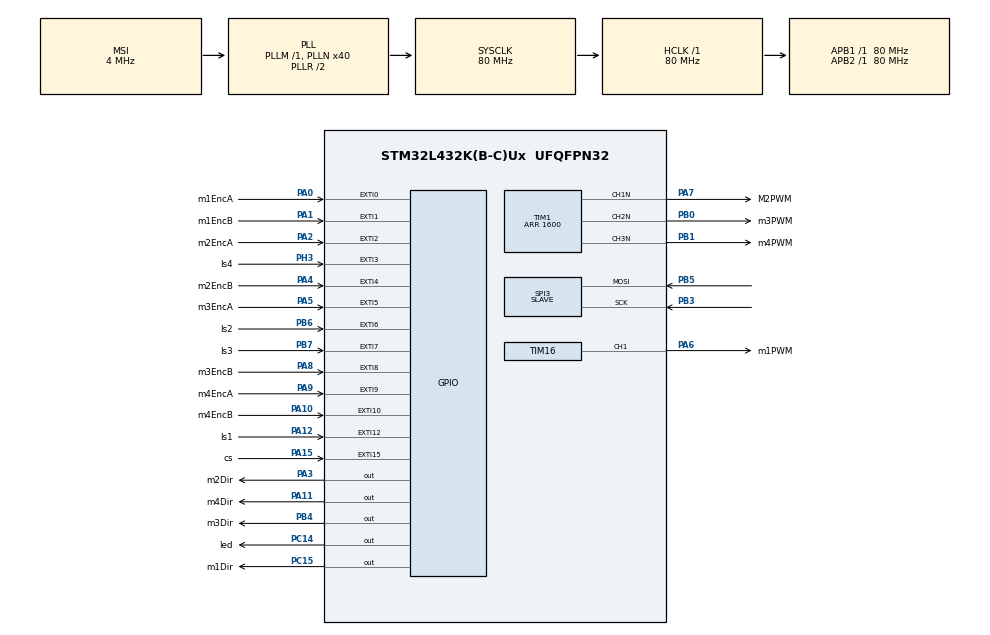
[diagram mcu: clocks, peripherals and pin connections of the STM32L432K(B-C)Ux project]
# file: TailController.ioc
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Dma.Request0=SPI3_RX
Dma.SPI3_RX.0.Direction=DMA_PERIPH_TO_MEMORY
Dma.SPI3_RX.0.Instance=DMA2_Channel1
Dma.SPI3_RX.0.MemDataAlignment=DMA_MDATAALIGN_HALFWORD
Dma.SPI3_RX.0.MemInc=DMA_MINC_ENABLE
Dma.SPI3_RX.0.Mode=DMA_NORMAL
Dma.SPI3_RX.0.PeriphDataAlignment=DMA_PDATAALIGN_HALFWORD
Dma.SPI3_RX.0.PeriphInc=DMA_PINC_DISABLE
Dma.SPI3_RX.0.Priority=DMA_PRIORITY_HIGH
Mcu.Family=STM32L4
Mcu.Name=STM32L432K(B-C)Ux
Mcu.Package=UFQFPN32
NVIC.DMA2_Channel1_IRQn=true\:0\:0\:false\:false\:true\:false\:true
NVIC.EXTI0_IRQn=true\:0\:0\:false\:false\:true\:true\:true
NVIC.EXTI15_10_IRQn=true\:0\:0\:false\:false\:true\:true\:true
NVIC.EXTI1_IRQn=true\:0\:0\:false\:false\:true\:true\:true
NVIC.EXTI2_IRQn=true\:0\:0\:false\:false\:true\:true\:true
NVIC.EXTI3_IRQn=true\:0\:0\:false\:false\:true\:true\:true
NVIC.EXTI4_IRQn=true\:0\:0\:false\:false\:true\:true\:true
NVIC.EXTI9_5_IRQn=true\:0\:0\:false\:false\:true\:true\:true
NVIC.PriorityGroup=NVIC_PRIORITYGROUP_4
NVIC.TIM7_IRQn=true\:0\:0\:false\:false\:true\:true\:true
PA0.GPIO_Label=m1EncA
PA0.Signal=SharedStack_PA0
PA0.Stacked=true
PA1.GPIO_Label=m1EncB
PA1.Signal=SharedStack_PA1
PA1.Stacked=true
PA10.GPIO_Label=m4EncB
PA10.Signal=SharedStack_PA10
PA10.Stacked=true
PA11.GPIO_Label=m4Dir
PA11.GPIO_ModeDefaultOutputPP=GPIO_MODE_OUTPUT_PP
PA11.GPIO_PuPd=GPIO_PULLDOWN
PA11.GPIO_Speed=GPIO_SPEED_FREQ_LOW
PA11.PinState=GPIO_PIN_RESET
PA11.Signal=GPIO_Output
PA12.GPIO_Label=ls1
PA12.Signal=GPXTI12
PA13\ (JTMS-SWDIO).Mode=Serial_Wire
PA13\ (JTMS-SWDIO).Signal=SYS_JTMS-SWDIO
PA14\ (JTCK-SWCLK).Mode=Serial_Wire
PA14\ (JTCK-SWCLK).Signal=SYS_JTCK-SWCLK
PA15\ (JTDI).GPIO_Label=cs
PA15\ (JTDI).Signal=GPXTI15
PA2.GPIO_Label=m2EncA
PA2.Signal=SharedStack_PA2
PA2.Stacked=true
PA3.GPIO_Label=m2Dir
PA3.GPIO_ModeDefaultOutputPP=GPIO_MODE_OUTPUT_PP
PA3.GPIO_PuPd=GPIO_PULLDOWN
PA3.GPIO_Speed=GPIO_SPEED_FREQ_LOW
PA3.PinState=GPIO_PIN_RESET
PA3.Signal=GPIO_Output
PA4.GPIO_Label=m2EncB
PA4.Signal=SharedStack_PA4
PA4.Stacked=true
PA5.GPIO_Label=m3EncA
PA5.Signal=SharedStack_PA5
PA5.Stacked=true
PA6.GPIO_Label=m1PWM
PA6.Signal=S_TIM16_CH1
PA7.GPIO_Label=M2PWM
PA7.GPIO_Speed=GPIO_SPEED_FREQ_VERY_HIGH
PA7.Mode=PWM Generation1 CH1N
PA7.Signal=TIM1_CH1N
PA8.GPIO_Label=m3EncB
PA8.Signal=SharedStack_PA8
PA8.Stacked=true
PA9.GPIO_Label=m4EncA
PA9.Signal=SharedStack_PA9
PA9.Stacked=true
PB0.GPIO_Label=m3PWM
PB0.GPIO_Speed=GPIO_SPEED_FREQ_VERY_HIGH
PB0.Mode=PWM Generation2 CH2N
PB0.Signal=TIM1_CH2N
PB1.GPIO_Label=m4PWM
PB1.GPIO_Speed=GPIO_SPEED_FREQ_VERY_HIGH
PB1.Mode=PWM Generation3 CH3N
PB1.Signal=TIM1_CH3N
PB3\ (JTDO-TRACESWO).Mode=RX_Only_Simplex_Unidirect_Slave
PB3\ (JTDO-TRACESWO).Signal=SPI3_SCK
PB4\ (NJTRST).GPIO_Label=m3Dir
PB4\ (NJTRST).GPIO_ModeDefaultOutputPP=GPIO_MODE_OUTPUT_PP
PB4\ (NJTRST).GPIO_PuPd=GPIO_PULLDOWN
PB4\ (NJTRST).GPIO_Speed=GPIO_SPEED_FREQ_LOW
PB4\ (NJTRST).PinState=GPIO_PIN_RESET
PB4\ (NJTRST).Signal=GPIO_Output
PB5.Mode=RX_Only_Simplex_Unidirect_Slave
PB5.Signal=SPI3_MOSI
PB6.GPIO_Label=ls2
PB6.Signal=GPXTI6
PB7.GPIO_Label=ls3
PB7.Signal=GPXTI7
PC14-OSC32_IN\ (PC14).GPIO_Label=led
PC14-OSC32_IN\ (PC14).GPIO_ModeDefaultOutputPP=GPIO_MODE_OUTPUT_PP
PC14-OSC32_IN\ (PC14).GPIO_PuPd=GPIO_PULLDOWN
PC14-OSC32_IN\ (PC14).GPIO_Speed=GPIO_SPEED_FREQ_LOW
PC14-OSC32_IN\ (PC14).PinState=GPIO_PIN_RESET
PC14-OSC32_IN\ (PC14).Signal=GPIO_Output
PC15-OSC32_OUT\ (PC15).GPIO_Label=m1Dir
PC15-OSC32_OUT\ (PC15).GPIO_ModeDefaultOutputPP=GPIO_MODE_OUTPUT_PP
PC15-OSC32_OUT\ (PC15).GPIO_PuPd=GPIO_PULLDOWN
PC15-OSC32_OUT\ (PC15).GPIO_Speed=GPIO_SPEED_FREQ_LOW
PC15-OSC32_OUT\ (PC15).PinState=GPIO_PIN_RESET
PC15-OSC32_OUT\ (PC15).Signal=GPIO_Output
PH3-BOOT0.GPIO_Label=ls4
PH3-BOOT0.Signal=GPXTI3
ProjectManager.HeapSize=0x200
ProjectManager.StackSize=0x400
ProjectManager.TargetToolchain=SW4STM32
RCC.AHBFreq_Value=80000000
RCC.APB1Freq_Value=80000000
RCC.APB1TimFreq_Value=80000000
RCC.APB2Freq_Value=80000000
RCC.APB2TimFreq_Value=80000000
RCC.CortexFreq_Value=80000000
RCC.HCLKFreq_Value=80000000
RCC.HSE_VALUE=8000000
RCC.HSI48_VALUE=48000000
RCC.HSI_VALUE=16000000
RCC.LSE_VALUE=32768
RCC.MSI_VALUE=4000000
RCC.PLLN=40
RCC.SYSCLKFreq_VALUE=80000000
RCC.SYSCLKSource=RCC_SYSCLKSOURCE_PLLCLK
RCC.VCOOutputFreq_Value=160000000
SH.S_TIM16_CH1.0=TIM16_CH1,PWM Generation1 CH1
SH.SharedStack_PA0.0=GPIO_EXTI0
SH.SharedStack_PA0.1=GPIO_Input+0
SH.SharedStack_PA1.0=GPIO_EXTI1
SH.SharedStack_PA1.1=GPIO_Input+0
SH.SharedStack_PA10.0=GPIO_EXTI10
SH.SharedStack_PA10.1=GPIO_Input+0
SH.SharedStack_PA2.0=GPIO_EXTI2
SH.SharedStack_PA2.1=GPIO_Input+0
SH.SharedStack_PA4.0=GPIO_EXTI4
SH.SharedStack_PA4.1=GPIO_Input+0
SH.SharedStack_PA5.0=GPIO_EXTI5
SH.SharedStack_PA5.1=GPIO_Input+0
SH.SharedStack_PA8.0=GPIO_EXTI8
SH.SharedStack_PA8.1=GPIO_Input+0
SH.SharedStack_PA9.0=GPIO_EXTI9
SH.SharedStack_PA9.1=GPIO_Input+0
SPI3.DataSize=SPI_DATASIZE_16BIT
SPI3.Direction=SPI_DIRECTION_2LINES_RXONLY
SPI3.Mode=SPI_MODE_SLAVE
SPI3.VirtualType=VM_SLAVE
TIM1.Channel-PWM\ Generation1\ CH1N=TIM_CHANNEL_1
TIM1.Channel-PWM\ Generation2\ CH2N=TIM_CHANNEL_2
TIM1.Channel-PWM\ Generation3\ CH3N=TIM_CHANNEL_3
TIM1.OCFastMode_PWM-PWM\ Generation1\ CH1N=TIM_OCFAST_ENABLE
TIM1.OCFastMode_PWM-PWM\ Generation2\ CH2N=TIM_OCFAST_ENABLE
TIM1.OCFastMode_PWM-PWM\ Generation3\ CH3N=TIM_OCFAST_ENABLE
TIM1.Period=1600
TIM1.Pulse-PWM\ Generation1\ CH1N=800
TIM1.Pulse-PWM\ Generation2\ CH2N=800
TIM1.Pulse-PWM\ Generation3\ CH3N=800
TIM1.RepetitionCounter=0
TIM16.Channel=TIM_CHANNEL_1
TIM16.Prescaler=1600
TIM16.Pulse=800
TIM7.Period=1000
VP_TIM16_VS_ClockSourceINT.Mode=Enable_Timer
VP_TIM7_VS_ClockSourceINT.Mode=Enable_Timer
board=custom

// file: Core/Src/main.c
/* USER CODE BEGIN Header */
/**
 ******************************************************************************
 * @file           : main.c
 * @brief          : Main program body
 ******************************************************************************
 * @attention
 *
 * <h2><center>&copy; Copyright (c) 2019 STMicroelectronics.
 * All rights reserved.</center></h2>
 *
 * This software component is licensed by ST under BSD 3-Clause license,
 * the "License"; You may not use this file except in compliance with the
 * License. You may obtain a copy of the License at:
 *                        opensource.org/licenses/BSD-3-Clause
 *
 ******************************************************************************
 */
/* USER CODE END Header */

#include "main.h"
#include <stdbool.h>
#include "PID.h"

/* USER CODE BEGIN PM */
#define PWM_Period 18000

/* USER CODE END PM */

SPI_HandleTypeDef hspi3;
DMA_HandleTypeDef hdma_spi3_rx;

TIM_HandleTypeDef htim1;
TIM_HandleTypeDef htim7;
TIM_HandleTypeDef htim16;

extern int64_t m1Enc ,m2Enc, m3Enc, m4Enc;
int m1A, m1B, m2A, m2B, m3A, m3B, m4A, m4B;
float M1Out, M2Out, M3Out, M4Out;

extern bool m1Homed, m2Homed , m3Homed , m4Homed ;

PidType M1 ;
PidType M2 ;
PidType M3 ;
PidType M4 ;

int64_t M1SetPoint, M2SetPoint, M3SetPoint, M4SetPoint;
int16_t _TXData[6];

void SystemClock_Config(void);
static void MX_GPIO_Init(void);
static void MX_DMA_Init(void);
static void MX_TIM1_Init(void);
static void MX_TIM16_Init(void);
static void MX_SPI3_Init(void);
static void MX_TIM7_Init(void);
void runControllers(void);
void HomeMotors(int motor);
void ConfigCOntrollers();
int PCLK1_Freq;

int main(void)
{

	/* MCU Configuration--------------------------------------------------------*/

	/* Reset of all peripherals, Initializes the Flash interface and the Systick. */
	HAL_Init();

	/* Configure the system clock */
	SystemClock_Config();

	/* Initialize all configured peripherals */
	MX_GPIO_Init();
	MX_DMA_Init();
	MX_TIM1_Init();
	MX_TIM16_Init();
	MX_SPI3_Init();
	MX_TIM7_Init();
	ConfigControllers();

	M1SetPoint = 342000;
	M2SetPoint = 342000;
	M3SetPoint = 342000;
	M4SetPoint = 300;

	PCLK1_Freq = HAL_RCC_GetPCLK2Freq();
	if (HAL_TIM_PWM_Start(&htim16, TIM_CHANNEL_1) != HAL_OK)
	{
		Error_Handler();
	}
	if (HAL_TIMEx_PWMN_Start(&htim1, TIM_CHANNEL_1) != HAL_OK)
	{
		Error_Handler();
	}
	if (HAL_TIMEx_PWMN_Start(&htim1, TIM_CHANNEL_2) != HAL_OK)
	{
		Error_Handler();
	}
	if (HAL_TIMEx_PWMN_Start(&htim1, TIM_CHANNEL_3) != HAL_OK)
	{
		Error_Handler();
	}
	__HAL_TIM_SET_AUTORELOAD(&htim16, PCLK1_Freq / PWM_Period);

	__HAL_TIM_SET_AUTORELOAD(&htim1, PCLK1_Freq / PWM_Period);

	HAL_TIM_Base_Start(&htim16);
	HAL_TIM_Base_Start(&htim1);

	HAL_TIM_MspPostInit(&htim1);
	HAL_TIM_MspPostInit(&htim16);
	//
	__HAL_TIM_SET_COMPARE(&htim16, TIM_CHANNEL_1, 0);
	__HAL_TIM_SET_COMPARE(&htim1, TIM_CHANNEL_1,0);
	__HAL_TIM_SET_COMPARE(&htim1, TIM_CHANNEL_2,0);
	__HAL_TIM_SET_COMPARE(&htim1, TIM_CHANNEL_3,0);
	//	/* USER CODE BEGIN 2 */
	//
	//	//TODO: Init controller variables here
	//
	//	/* USER CODE END 2 */
	//	HomeMotors(1);
	//	HomeMotors(2);
	//	HomeMotors(3);
	//	HomeMotors(4);

	HAL_SPI_Receive_DMA(&hspi3, _TXData, 6);
	//
	MX_TIM7_Init();
	HAL_TIM_Base_Start(&htim7);

	__HAL_TIM_SET_COUNTER(&htim7, 1);
	__HAL_TIM_ENABLE_IT(&htim7, TIM_IT_UPDATE);
	//

	while (1)
	{
		HAL_GPIO_TogglePin(led_GPIO_Port, led_Pin);
		HAL_Delay(100);
		__HAL_TIM_SET_COMPARE(&htim16, TIM_CHANNEL_1, PCLK1_Freq / PWM_Period * 0.2 );
		__HAL_TIM_SET_COMPARE(&htim1, TIM_CHANNEL_1, PCLK1_Freq / PWM_Period * 0.2 );
		__HAL_TIM_SET_COMPARE(&htim1, TIM_CHANNEL_2, PCLK1_Freq / PWM_Period * 0.2 );
		__HAL_TIM_SET_COMPARE(&htim1, TIM_CHANNEL_3, PCLK1_Freq / PWM_Period * 0.2 );

		/* USER CODE END WHILE */

	}
}

void SystemClock_Config(void)
{
	RCC_OscInitTypeDef RCC_OscInitStruct = {0};
	RCC_ClkInitTypeDef RCC_ClkInitStruct = {0};

	/** Initializes the CPU, AHB and APB busses clocks
	 */
	RCC_OscInitStruct.OscillatorType = RCC_OSCILLATORTYPE_MSI;
	RCC_OscInitStruct.MSIState = RCC_MSI_ON;
	RCC_OscInitStruct.MSICalibrationValue = 0;
	RCC_OscInitStruct.MSIClockRange = RCC_MSIRANGE_6;
	RCC_OscInitStruct.PLL.PLLState = RCC_PLL_ON;
	RCC_OscInitStruct.PLL.PLLSource = RCC_PLLSOURCE_MSI;
	RCC_OscInitStruct.PLL.PLLM = 1;
	RCC_OscInitStruct.PLL.PLLN = 40;
	RCC_OscInitStruct.PLL.PLLP = RCC_PLLP_DIV7;
	RCC_OscInitStruct.PLL.PLLQ = RCC_PLLQ_DIV2;
	RCC_OscInitStruct.PLL.PLLR = RCC_PLLR_DIV2;
	if (HAL_RCC_OscConfig(&RCC_OscInitStruct) != HAL_OK)
	{
		Error_Handler();
	}
	/** Initializes the CPU, AHB and APB busses clocks
	 */
	RCC_ClkInitStruct.ClockType = RCC_CLOCKTYPE_HCLK|RCC_CLOCKTYPE_SYSCLK
			|RCC_CLOCKTYPE_PCLK1|RCC_CLOCKTYPE_PCLK2;
	RCC_ClkInitStruct.SYSCLKSource = RCC_SYSCLKSOURCE_PLLCLK;
	RCC_ClkInitStruct.AHBCLKDivider = RCC_SYSCLK_DIV1;
	RCC_ClkInitStruct.APB1CLKDivider = RCC_HCLK_DIV1;
	RCC_ClkInitStruct.APB2CLKDivider = RCC_HCLK_DIV1;

	if (HAL_RCC_ClockConfig(&RCC_ClkInitStruct, FLASH_LATENCY_4) != HAL_OK)
	{
		Error_Handler();
	}
	/** Configure the main internal regulator output voltage
	 */
	if (HAL_PWREx_ControlVoltageScaling(PWR_REGULATOR_VOLTAGE_SCALE1) != HAL_OK)
	{
		Error_Handler();
	}
}

static void MX_SPI3_Init(void)
{

	/* SPI3 parameter configuration*/
	hspi3.Instance = SPI3;
	hspi3.Init.Mode = SPI_MODE_SLAVE;
	hspi3.Init.Direction = SPI_DIRECTION_2LINES_RXONLY;
	hspi3.Init.DataSize = SPI_DATASIZE_16BIT;
	hspi3.Init.CLKPolarity = SPI_POLARITY_LOW;
	hspi3.Init.CLKPhase = SPI_PHASE_1EDGE;
	hspi3.Init.NSS = SPI_NSS_SOFT;
	hspi3.Init.FirstBit = SPI_FIRSTBIT_MSB;
	hspi3.Init.TIMode = SPI_TIMODE_DISABLE;
	hspi3.Init.CRCCalculation = SPI_CRCCALCULATION_DISABLE;
	hspi3.Init.CRCPolynomial = 7;
	hspi3.Init.CRCLength = SPI_CRC_LENGTH_DATASIZE;
	hspi3.Init.NSSPMode = SPI_NSS_PULSE_DISABLE;
	if (HAL_SPI_Init(&hspi3) != HAL_OK)
	{
		Error_Handler();
	}

}

static void MX_TIM1_Init(void)
{

	TIM_MasterConfigTypeDef sMasterConfig = {0};
	TIM_OC_InitTypeDef sConfigOC = {0};
	TIM_BreakDeadTimeConfigTypeDef sBreakDeadTimeConfig = {0};

	htim1.Instance = TIM1;
	htim1.Init.Prescaler = 0;
	htim1.Init.CounterMode = TIM_COUNTERMODE_UP;
	htim1.Init.Period = 0;
	htim1.Init.ClockDivision = TIM_CLOCKDIVISION_DIV1;
	htim1.Init.RepetitionCounter = 0;
	htim1.Init.AutoReloadPreload = TIM_AUTORELOAD_PRELOAD_DISABLE;
	if (HAL_TIM_PWM_Init(&htim1) != HAL_OK)
	{
		Error_Handler();
	}
	sMasterConfig.MasterOutputTrigger = TIM_TRGO_RESET;
	sMasterConfig.MasterOutputTrigger2 = TIM_TRGO2_RESET;
	sMasterConfig.MasterSlaveMode = TIM_MASTERSLAVEMODE_DISABLE;
	if (HAL_TIMEx_MasterConfigSynchronization(&htim1, &sMasterConfig) != HAL_OK)
	{
		Error_Handler();
	}
	sConfigOC.OCMode = TIM_OCMODE_PWM1;
	sConfigOC.Pulse = 800;
	sConfigOC.OCPolarity = TIM_OCPOLARITY_HIGH;
	sConfigOC.OCNPolarity = TIM_OCNPOLARITY_HIGH;
	sConfigOC.OCFastMode = TIM_OCFAST_ENABLE;
	sConfigOC.OCIdleState = TIM_OCIDLESTATE_RESET;
	sConfigOC.OCNIdleState = TIM_OCNIDLESTATE_RESET;
	if (HAL_TIM_PWM_ConfigChannel(&htim1, &sConfigOC, TIM_CHANNEL_1) != HAL_OK)
	{
		Error_Handler();
	}
	if (HAL_TIM_PWM_ConfigChannel(&htim1, &sConfigOC, TIM_CHANNEL_2) != HAL_OK)
	{
		Error_Handler();
	}
	if (HAL_TIM_PWM_ConfigChannel(&htim1, &sConfigOC, TIM_CHANNEL_3) != HAL_OK)
	{
		Error_Handler();
	}
	sBreakDeadTimeConfig.OffStateRunMode = TIM_OSSR_DISABLE;
	sBreakDeadTimeConfig.OffStateIDLEMode = TIM_OSSI_DISABLE;
	sBreakDeadTimeConfig.LockLevel = TIM_LOCKLEVEL_OFF;
	sBreakDeadTimeConfig.DeadTime = 0;
	sBreakDeadTimeConfig.BreakState = TIM_BREAK_DISABLE;
	sBreakDeadTimeConfig.BreakPolarity = TIM_BREAKPOLARITY_HIGH;
	sBreakDeadTimeConfig.BreakFilter = 0;
	sBreakDeadTimeConfig.Break2State = TIM_BREAK2_DISABLE;
	sBreakDeadTimeConfig.Break2Polarity = TIM_BREAK2POLARITY_HIGH;
	sBreakDeadTimeConfig.Break2Filter = 0;
	sBreakDeadTimeConfig.AutomaticOutput = TIM_AUTOMATICOUTPUT_DISABLE;
	if (HAL_TIMEx_ConfigBreakDeadTime(&htim1, &sBreakDeadTimeConfig) != HAL_OK)
	{
		Error_Handler();
	}
	HAL_TIM_MspPostInit(&htim1);

}

static void MX_TIM7_Init(void)
{

	TIM_MasterConfigTypeDef sMasterConfig = {0};

	htim7.Instance = TIM7;
	htim7.Init.Prescaler = 0;
	htim7.Init.CounterMode = TIM_COUNTERMODE_UP;
	htim7.Init.Period = 10000;
	htim7.Init.AutoReloadPreload = TIM_AUTORELOAD_PRELOAD_DISABLE;
	if (HAL_TIM_Base_Init(&htim7) != HAL_OK)
	{
		Error_Handler();
	}
	sMasterConfig.MasterOutputTrigger = TIM_TRGO_RESET;
	sMasterConfig.MasterSlaveMode = TIM_MASTERSLAVEMODE_DISABLE;
	if (HAL_TIMEx_MasterConfigSynchronization(&htim7, &sMasterConfig) != HAL_OK)
	{
		Error_Handler();
	}

}

static void MX_TIM16_Init(void)
{

	TIM_OC_InitTypeDef sConfigOC = {0};
	TIM_BreakDeadTimeConfigTypeDef sBreakDeadTimeConfig = {0};

	htim16.Instance = TIM16;
	htim16.Init.Prescaler = 0;
	htim16.Init.CounterMode = TIM_COUNTERMODE_UP;
	htim16.Init.Period = 0;
	htim16.Init.ClockDivision = TIM_CLOCKDIVISION_DIV1;
	htim16.Init.RepetitionCounter = 0;
	htim16.Init.AutoReloadPreload = TIM_AUTORELOAD_PRELOAD_DISABLE;
	if (HAL_TIM_Base_Init(&htim16) != HAL_OK)
	{
		Error_Handler();
	}
	if (HAL_TIM_PWM_Init(&htim16) != HAL_OK)
	{
		Error_Handler();
	}
	sConfigOC.OCMode = TIM_OCMODE_PWM1;
	sConfigOC.Pulse = 800;
	sConfigOC.OCPolarity = TIM_OCPOLARITY_HIGH;
	sConfigOC.OCNPolarity = TIM_OCNPOLARITY_HIGH;
	sConfigOC.OCFastMode = TIM_OCFAST_DISABLE;
	sConfigOC.OCIdleState = TIM_OCIDLESTATE_RESET;
	sConfigOC.OCNIdleState = TIM_OCNIDLESTATE_RESET;
	if (HAL_TIM_PWM_ConfigChannel(&htim16, &sConfigOC, TIM_CHANNEL_1) != HAL_OK)
	{
		Error_Handler();
	}
	sBreakDeadTimeConfig.OffStateRunMode = TIM_OSSR_DISABLE;
	sBreakDeadTimeConfig.OffStateIDLEMode = TIM_OSSI_DISABLE;
	sBreakDeadTimeConfig.LockLevel = TIM_LOCKLEVEL_OFF;
	sBreakDeadTimeConfig.DeadTime = 0;
	sBreakDeadTimeConfig.BreakState = TIM_BREAK_DISABLE;
	sBreakDeadTimeConfig.BreakPolarity = TIM_BREAKPOLARITY_HIGH;
	sBreakDeadTimeConfig.AutomaticOutput = TIM_AUTOMATICOUTPUT_DISABLE;
	if (HAL_TIMEx_ConfigBreakDeadTime(&htim16, &sBreakDeadTimeConfig) != HAL_OK)
	{
		Error_Handler();
	}
	HAL_TIM_MspPostInit(&htim16);

}

static void MX_DMA_Init(void)
{
	/* DMA controller clock enable */
	__HAL_RCC_DMA2_CLK_ENABLE();

	/* DMA interrupt init */
	/* DMA2_Channel1_IRQn interrupt configuration */
	HAL_NVIC_SetPriority(DMA2_Channel1_IRQn, 0, 0);
	HAL_NVIC_EnableIRQ(DMA2_Channel1_IRQn);

}

static void MX_GPIO_Init(void)
{
	GPIO_InitTypeDef GPIO_InitStruct = {0};

	/* GPIO Ports Clock Enable */
	__HAL_RCC_GPIOC_CLK_ENABLE();
	__HAL_RCC_GPIOA_CLK_ENABLE();
	__HAL_RCC_GPIOB_CLK_ENABLE();
	__HAL_RCC_GPIOH_CLK_ENABLE();

	/*Configure GPIO pin Output Level */
	HAL_GPIO_WritePin(GPIOC, led_Pin|m1Dir_Pin, GPIO_PIN_RESET);

	/*Configure GPIO pin Output Level */
	HAL_GPIO_WritePin(GPIOA, m2Dir_Pin|m4Dir_Pin, GPIO_PIN_RESET);

	/*Configure GPIO pin Output Level */
	HAL_GPIO_WritePin(m3Dir_GPIO_Port, m3Dir_Pin, GPIO_PIN_RESET);

	/*Configure GPIO pins : led_Pin m1Dir_Pin */
	GPIO_InitStruct.Pin = led_Pin|m1Dir_Pin;
	GPIO_InitStruct.Mode = GPIO_MODE_OUTPUT_PP;
	GPIO_InitStruct.Pull = GPIO_PULLDOWN;
	GPIO_InitStruct.Speed = GPIO_SPEED_FREQ_LOW;
	HAL_GPIO_Init(GPIOC, &GPIO_InitStruct);

	/*Configure GPIO pins : m1EncA_Pin m1EncB_Pin m2EncA_Pin m2EncB_Pin
                           m3EncA_Pin m3EncB_Pin m4EncA_Pin m4EncB_Pin
                           ls1_Pin cs_Pin */
	GPIO_InitStruct.Pin = m1EncA_Pin|m1EncB_Pin|m2EncA_Pin|m2EncB_Pin
			|m3EncA_Pin|m3EncB_Pin|m4EncA_Pin|m4EncB_Pin
			|ls1_Pin|cs_Pin;
	GPIO_InitStruct.Mode = GPIO_MODE_IT_RISING_FALLING;
	GPIO_InitStruct.Pull = GPIO_PULLDOWN;
	HAL_GPIO_Init(GPIOA, &GPIO_InitStruct);

	/*Configure GPIO pins : m2Dir_Pin m4Dir_Pin */
	GPIO_InitStruct.Pin = m2Dir_Pin|m4Dir_Pin;
	GPIO_InitStruct.Mode = GPIO_MODE_OUTPUT_PP;
	GPIO_InitStruct.Pull = GPIO_PULLDOWN;
	GPIO_InitStruct.Speed = GPIO_SPEED_FREQ_LOW;
	HAL_GPIO_Init(GPIOA, &GPIO_InitStruct);

	/*Configure GPIO pin : m3Dir_Pin */
	GPIO_InitStruct.Pin = m3Dir_Pin;
	GPIO_InitStruct.Mode = GPIO_MODE_OUTPUT_PP;
	GPIO_InitStruct.Pull = GPIO_PULLDOWN;
	GPIO_InitStruct.Speed = GPIO_SPEED_FREQ_LOW;
	HAL_GPIO_Init(m3Dir_GPIO_Port, &GPIO_InitStruct);

	/*Configure GPIO pins : ls2_Pin ls3_Pin */
	GPIO_InitStruct.Pin = ls2_Pin|ls3_Pin;
	GPIO_InitStruct.Mode = GPIO_MODE_IT_RISING;
	GPIO_InitStruct.Pull = GPIO_NOPULL;
	HAL_GPIO_Init(GPIOB, &GPIO_InitStruct);

	/*Configure GPIO pin : ls4_Pin */
	GPIO_InitStruct.Pin = ls4_Pin;
	GPIO_InitStruct.Mode = GPIO_MODE_IT_RISING;
	GPIO_InitStruct.Pull = GPIO_NOPULL;
	HAL_GPIO_Init(ls4_GPIO_Port, &GPIO_InitStruct);

	/* EXTI interrupt init*/
	HAL_NVIC_SetPriority(EXTI0_IRQn, 0, 0);
	HAL_NVIC_EnableIRQ(EXTI0_IRQn);

	HAL_NVIC_SetPriority(EXTI1_IRQn, 0, 0);
	HAL_NVIC_EnableIRQ(EXTI1_IRQn);

	HAL_NVIC_SetPriority(EXTI2_IRQn, 0, 0);
	HAL_NVIC_EnableIRQ(EXTI2_IRQn);

	HAL_NVIC_SetPriority(EXTI3_IRQn, 0, 0);
	HAL_NVIC_EnableIRQ(EXTI3_IRQn);

	HAL_NVIC_SetPriority(EXTI4_IRQn, 0, 0);
	HAL_NVIC_EnableIRQ(EXTI4_IRQn);

	HAL_NVIC_SetPriority(EXTI9_5_IRQn, 0, 0);
	HAL_NVIC_EnableIRQ(EXTI9_5_IRQn);

	HAL_NVIC_SetPriority(EXTI15_10_IRQn, 0, 0);
	HAL_NVIC_EnableIRQ(EXTI15_10_IRQn);

}

//                           _______         _______
//               Pin1 ______|       |_______|       |______ Pin1
// negative <---         _______         _______         __      --> positive
//               Pin2 __|       |_______|       |_______|   Pin2

//	new	     new	old	     old
//	pin2	pin1	pin2	pin1	Result
//	----	----	----	----	------
//	 0	      0	      0	      0	   no movement
//	 0	      0	      0	      1	     +1
//	 0	      0	      1	      0	     -1
//	 0        0	      1	      1		 +2  (assume pin1 edges only)
//	 0        1	      0	      0		 -1
//	 0        1	      0	      1		 no movement
//	 0        1	      1	      0		 -2  (assume pin1 edges only)
//	 0        1	      1	      1		 +1
//	 1        0	      0	      0		 +1
//	 1        0	      0	      1		 -2  (assume pin1 edges only)
//	 1        0	      1	      0		 no movement
//	 1        0	      1	      1		 -1
//	 1        1	      0	      0		 +2  (assume pin1 edges only)
//	 1        1	      0	      1		 -1
//	 1        1	      1	      0		 +1
//	 1        1	      1	      1		 no movement
/*
 *
 */

void HAL_GPIO_EXTI_Callback(uint16_t GPIO_Pin){

	//homing interrupts
	if(GPIO_Pin == GPIO_PIN_12){
		m1Homed = true;
		m1Enc = 0;
	}
	else if(GPIO_Pin == GPIO_PIN_6){
		m2Homed = true;
		m2Enc = 0;
	}
	else if(GPIO_Pin == GPIO_PIN_7){
		m3Homed = true;
		m3Enc = 0;
	}
	else if(GPIO_Pin == GPIO_PIN_3){
		m4Homed = true;
		m4Enc = 0;
	}

	//Encoder interrupts

	else if(GPIO_Pin == GPIO_PIN_0||GPIO_Pin == GPIO_PIN_1){//9cs
		int encA = HAL_GPIO_ReadPin(m1EncA_GPIO_Port, m1EncA_Pin);
		int encB = HAL_GPIO_ReadPin(m1EncB_GPIO_Port, m1EncB_Pin);
		if ((m1A == 0 && m1B == 0 && encA == 0 && encB == 0 )||
				(m1A == 0 && m1B == 1 && encA == 0 && encB == 1 )||
				(m1A == 1 && m1B == 0 && encA == 1 && encB == 0 )||
				(m1A == 1 && m1B == 1 && encA == 1 && encB == 1 )){
			m1Enc+=0;
		}
		else if ((m1A == 0 && m1B == 0 && encA == 0 && encB == 1)||
				(m1A == 0 && m1B == 1 && encA == 1 && encB == 1)||
				(m1A == 1 && m1B == 1 && encA == 1 && encB == 0)||
				(m1A == 1 && m1B == 0 && encA == 0 && encB == 0)){

			m1Enc+=1;
			m1A = encA;
			m1B = encB;

		}
		else if ((m1A == 0 && m1B == 0 && encA == 1 && encB == 0)||
				(m1A == 0 && m1B == 1 && encA == 0 && encB == 0)||
				(m1A == 1 && m1B == 0 &&encA == 1 && encB == 1)||
				(m1A == 1 && m1B == 1 && encA == 0 && encB == 1)){

			m1Enc-=1;
			m1A = encA;
			m1B = encB;

		}

	}
	else if(GPIO_Pin == GPIO_PIN_2||GPIO_Pin == GPIO_PIN_4){
		int encA = HAL_GPIO_ReadPin(m2EncA_GPIO_Port, m2EncA_Pin);
		int encB = HAL_GPIO_ReadPin(m2EncB_GPIO_Port, m2EncB_Pin);
		if ((m2A == 0 && m2B == 0 && encA == 0 && encB == 0 )||
				(m2A == 0 && m2B == 1 && encA == 0 && encB == 1 )||
				(m2A == 1 && m2B == 0 && encA == 1 && encB == 0 )||
				(m2A == 1 && m2B == 1 && encA == 1 && encB == 1 )){
			m2Enc+=0;
		}
		else if ((m2A == 0 && m2B == 0 && encA == 0 && encB == 1)||
				(m2A == 0 && m2B == 1 && encA == 1 && encB == 1)||
				(m2A == 1 && m2B == 1 && encA == 1 && encB == 0)||
				(m2A == 1 && m2B == 0 && encA == 0 && encB == 0)){

			m2Enc+=1;
			m2A = encA;
			m2B = encB;

		}
		else if ((m2A == 0 && m2B == 0 && encA == 1 && encB == 0)||
				(m2A == 0 && m2B == 1 && encA == 0 && encB == 0)||
				(m2A == 1 && m2B == 0 &&encA == 1 && encB == 1)||
				(m2A == 1 && m2B == 1 && encA == 0 && encB == 1)){

			m2Enc-=1;
			m2A = encA;
			m2B = encB;

		}

	}
	else if(GPIO_Pin == GPIO_PIN_5||GPIO_Pin == GPIO_PIN_8){
		int encA = HAL_GPIO_ReadPin(m3EncA_GPIO_Port, m3EncA_Pin);
		int encB = HAL_GPIO_ReadPin(m3EncB_GPIO_Port, m3EncB_Pin);
		if ((m3A == 0 && m3B == 0 && encA == 0 && encB == 0 )||
				(m3A == 0 && m3B == 1 && encA == 0 && encB == 1 )||
				(m3A == 1 && m3B == 0 && encA == 1 && encB == 0 )||
				(m3A == 1 && m3B == 1 && encA == 1 && encB == 1 )){
			//m3Enc+=0;
		}
		else if ((m3A == 0 && m3B == 0 && encA == 0 && encB == 1)||
				(m3A == 0 && m3B == 1 && encA == 1 && encB == 1)||
				(m3A == 1 && m3B == 1 && encA == 1 && encB == 0)||
				(m3A == 1 && m3B == 0 && encA == 0 && encB == 0)){

			m3Enc+=1;
			m3A = encA;
			m3B = encB;

		}
		else if ((m3A == 0 && m3B == 0 && encA == 1 && encB == 1)||
				(m3A == 0 && m3B == 1 && encA == 0 && encB == 1)||
				(m3A == 1 && m3B == 0 &&encA == 1 && encB == 0)||
				(m3A == 1 && m3B == 1 && encA == 0 && encB == 0)){

			m3Enc-=1;
			m3A = encA;
			m3B = encB;

		}

	}
	else if(GPIO_Pin == GPIO_PIN_9||GPIO_Pin == GPIO_PIN_10){
		int encA = HAL_GPIO_ReadPin(m4EncA_GPIO_Port, m4EncA_Pin);
		int encB = HAL_GPIO_ReadPin(m4EncB_GPIO_Port, m4EncB_Pin);
		if ((m4A == 0 && m4B == 0 && encA == 0 && encB == 0 )||
				(m4A == 0 && m4B == 1 && encA == 0 && encB == 1 )||
				(m4A == 1 && m4B == 0 && encA == 1 && encB == 0 )||
				(m4A == 1 && m4B == 1 && encA == 1 && encB == 1 )){
			m4Enc+=0;
		}
		else if ((m4A == 0 && m4B == 0 && encA == 0 && encB == 1)||
				(m4A == 0 && m4B == 1 && encA == 1 && encB == 1)||
				(m4A == 1 && m4B == 1 && encA == 1 && encB == 0)||
				(m4A == 1 && m4B == 0 && encA == 0 && encB == 0)){

			m4Enc++;
			m4A = encA;
			m4B = encB;

		}
		else if ((m4A == 0 && m4B == 0 && encA == 1 && encB == 0)||
				(m4A == 0 && m4B == 1 && encA == 0 && encB == 0)||
				(m4A == 1 && m4B == 0 &&encA == 1 && encB == 1)||
				(m4A == 1 && m4B == 1 && encA == 0 && encB == 1)){

			m4Enc--;
			m4A = encA;
			m4B = encB;

		}

	}
	else if (GPIO_Pin == GPIO_PIN_15){
		HAL_SPI_Receive_DMA(&hspi3, _TXData, 6);
		if(_TXData[0] == 0x22){
			//home

		}
		else if (_TXData[0] == 0x33){
			//tx[1] motor to set position in 2, 3, 4, 5
			if(_TXData[1] == 1){
				if(m1Homed){
					M1SetPoint = _TXData[2]<<48|_TXData[3]<<32|_TXData[4]<<16|_TXData[5];
				}
				else{
					return;
				}
			}

			else if(_TXData[1] == 2){
				if(m2Homed){
					M3SetPoint = _TXData[2]<<48|_TXData[3]<<32|_TXData[4]<<16|_TXData[5];
				}
				else{
					return;
				}
			}

			else if(_TXData[1] == 3){
				if(m3Homed){
					M3SetPoint = _TXData[2]<<48|_TXData[3]<<32|_TXData[4]<<16|_TXData[5];
				}
				else{
					return;
				}
			}

			else if(_TXData[1] == 4){
				if(m4Homed){
					M4SetPoint = _TXData[2]<<48|_TXData[3]<<32|_TXData[4]<<16|_TXData[5];
				}
				else{
					return;
				}
			}
		}
		else if(_TXData[0]==0xAA){
			//Set PIDS
			if(_TXData[1] == 1){

				PID_SetTunings(&M1, (float)(_TXData[2]/100), (float)(_TXData[3]/100), (float)(_TXData[4]/100));
			}

			else if(_TXData[1] == 2){
				PID_SetTunings(&M2, (float)(_TXData[2]/100), (float)(_TXData[3]/100), (float)(_TXData[4]/100));

			}

			else if(_TXData[1] == 3){
				PID_SetTunings(&M3, (float)(_TXData[2]/100), (float)(_TXData[3]/100), (float)(_TXData[4]/100));

			}

			else if(_TXData[1] == 4){
				PID_SetTunings(&M4, (float)(_TXData[2]/100), (float)(_TXData[3]/100), (float)(_TXData[4]/100));

			}
		}

	}

}

void runControllers(){

	M1.mySetpoint = M1SetPoint;
	M1.myInput = m1Enc;
	PID_Compute(&M1);
	M1Out = M1.myOutput;

	M2.mySetpoint = M2SetPoint;
	M2.myInput = m2Enc;
	PID_Compute(&M2);
	M2Out = M2.myOutput;

	M3.mySetpoint = M3SetPoint;
	M3.myInput = m3Enc;
	PID_Compute(&M3);
	M3Out = M3.myOutput;

	M4.mySetpoint = M4SetPoint;
	M4.myInput = m4Enc;
	PID_Compute(&M4);
	M4Out = M4.myOutput;

	if(M1Out>0){
		m1Dir_GPIO_Port->ODR |= m1Dir_Pin; //Set m1Dir pin high

	}
	else if (M1Out<0){
		m1Dir_GPIO_Port->ODR &= ~m1Dir_Pin; //Set m1Dir pin Low
		HAL_GPIO_WritePin(m1Dir_GPIO_Port, m1Dir_Pin, GPIO_PIN_SET);
		M1Out = M1Out*-1;

	}
	else if(M1Out == 0){

	}
	__HAL_TIM_SET_COMPARE(&htim16, TIM_CHANNEL_1, PCLK1_Freq / PWM_Period * M1Out );

	if(M2Out>0){
		m2Dir_GPIO_Port->ODR |= m2Dir_Pin; //Set m1Dir pin high

	}
	else if (M2Out<0){
		m2Dir_GPIO_Port->ODR &= ~m2Dir_Pin; //Set m1Dir pin Low
		M2Out = M2Out*-1;

	}
	else if(M2Out == 0){

	}
	__HAL_TIM_SET_COMPARE(&htim1, TIM_CHANNEL_1, PCLK1_Freq / PWM_Period * M2Out );

	if(M3Out>0){
		m3Dir_GPIO_Port->ODR |= m3Dir_Pin; //Set m1Dir pin high

	}
	else if (M3Out<0){
		m3Dir_GPIO_Port->ODR &= ~m3Dir_Pin; //Set m1Dir pin Low
		M3Out = M3Out*-1;

	}
	else if(M3Out == 0){

	}
	__HAL_TIM_SET_COMPARE(&htim1, TIM_CHANNEL_2, PCLK1_Freq / PWM_Period * M3Out );

	if(M4Out>0){
		HAL_GPIO_WritePin(m4Dir_GPIO_Port, m4Dir_Pin, GPIO_PIN_SET);

	}
	else if (M4Out<0){
		HAL_GPIO_WritePin(m4Dir_GPIO_Port, m4Dir_Pin, GPIO_PIN_RESET);
		M4Out = M4Out+1;

	}
	else if(M4Out == 0){

	}
	__HAL_TIM_SET_COMPARE(&htim1, TIM_CHANNEL_3, PCLK1_Freq / PWM_Period * M4Out );

}

void HomeMotors(int motor){

	if(motor == 1){
		while(!m1Homed){
			m1Dir_GPIO_Port->ODR |= m1Dir_Pin; //this may have to be inverted at test time
			__HAL_TIM_SET_COMPARE(&htim16, TIM_CHANNEL_1, PCLK1_Freq / PWM_Period * 0.1 );

		}
	}
	else if(motor == 2){
		while(!m2Homed){
			m2Dir_GPIO_Port->ODR |= m2Dir_Pin; //this may have to be inverted at test time
			__HAL_TIM_SET_COMPARE(&htim1, TIM_CHANNEL_1, PCLK1_Freq / PWM_Period * 0.1 );

		}
	}
	else if(motor == 3){
		while(!m3Homed){
			m3Dir_GPIO_Port->ODR |= m3Dir_Pin; //this may have to be inverted at test time
			__HAL_TIM_SET_COMPARE(&htim1, TIM_CHANNEL_2, PCLK1_Freq / PWM_Period * 0.1 );

		}
	}
	else if(motor == 4){
		while(!m4Homed){
			m4Dir_GPIO_Port->ODR |= m4Dir_Pin; //this may have to be inverted at test time
			__HAL_TIM_SET_COMPARE(&htim1, TIM_CHANNEL_3, PCLK1_Freq / PWM_Period * 0.1 );

		}
	}

}

void ConfigControllers(){
	PID_init(&M1, 10, 0, 0, 0);
	PID_SetOutputLimits(&M1, -0.4, 0.4);
	PID_init(&M2, 10, 0, 0, 0);
	PID_SetOutputLimits(&M2, -0.4, 0.4);
	PID_init(&M3, 10, 0, 0, 0);
	PID_SetOutputLimits(&M3, -0.4, 0.4);
	PID_init(&M4, 10, 0, 0, 0);
	PID_SetOutputLimits(&M4, -0.4, 0.4);

}

void Error_Handler(void)
{
}

/************************ (C) COPYRIGHT STMicroelectronics *****END OF FILE****/
